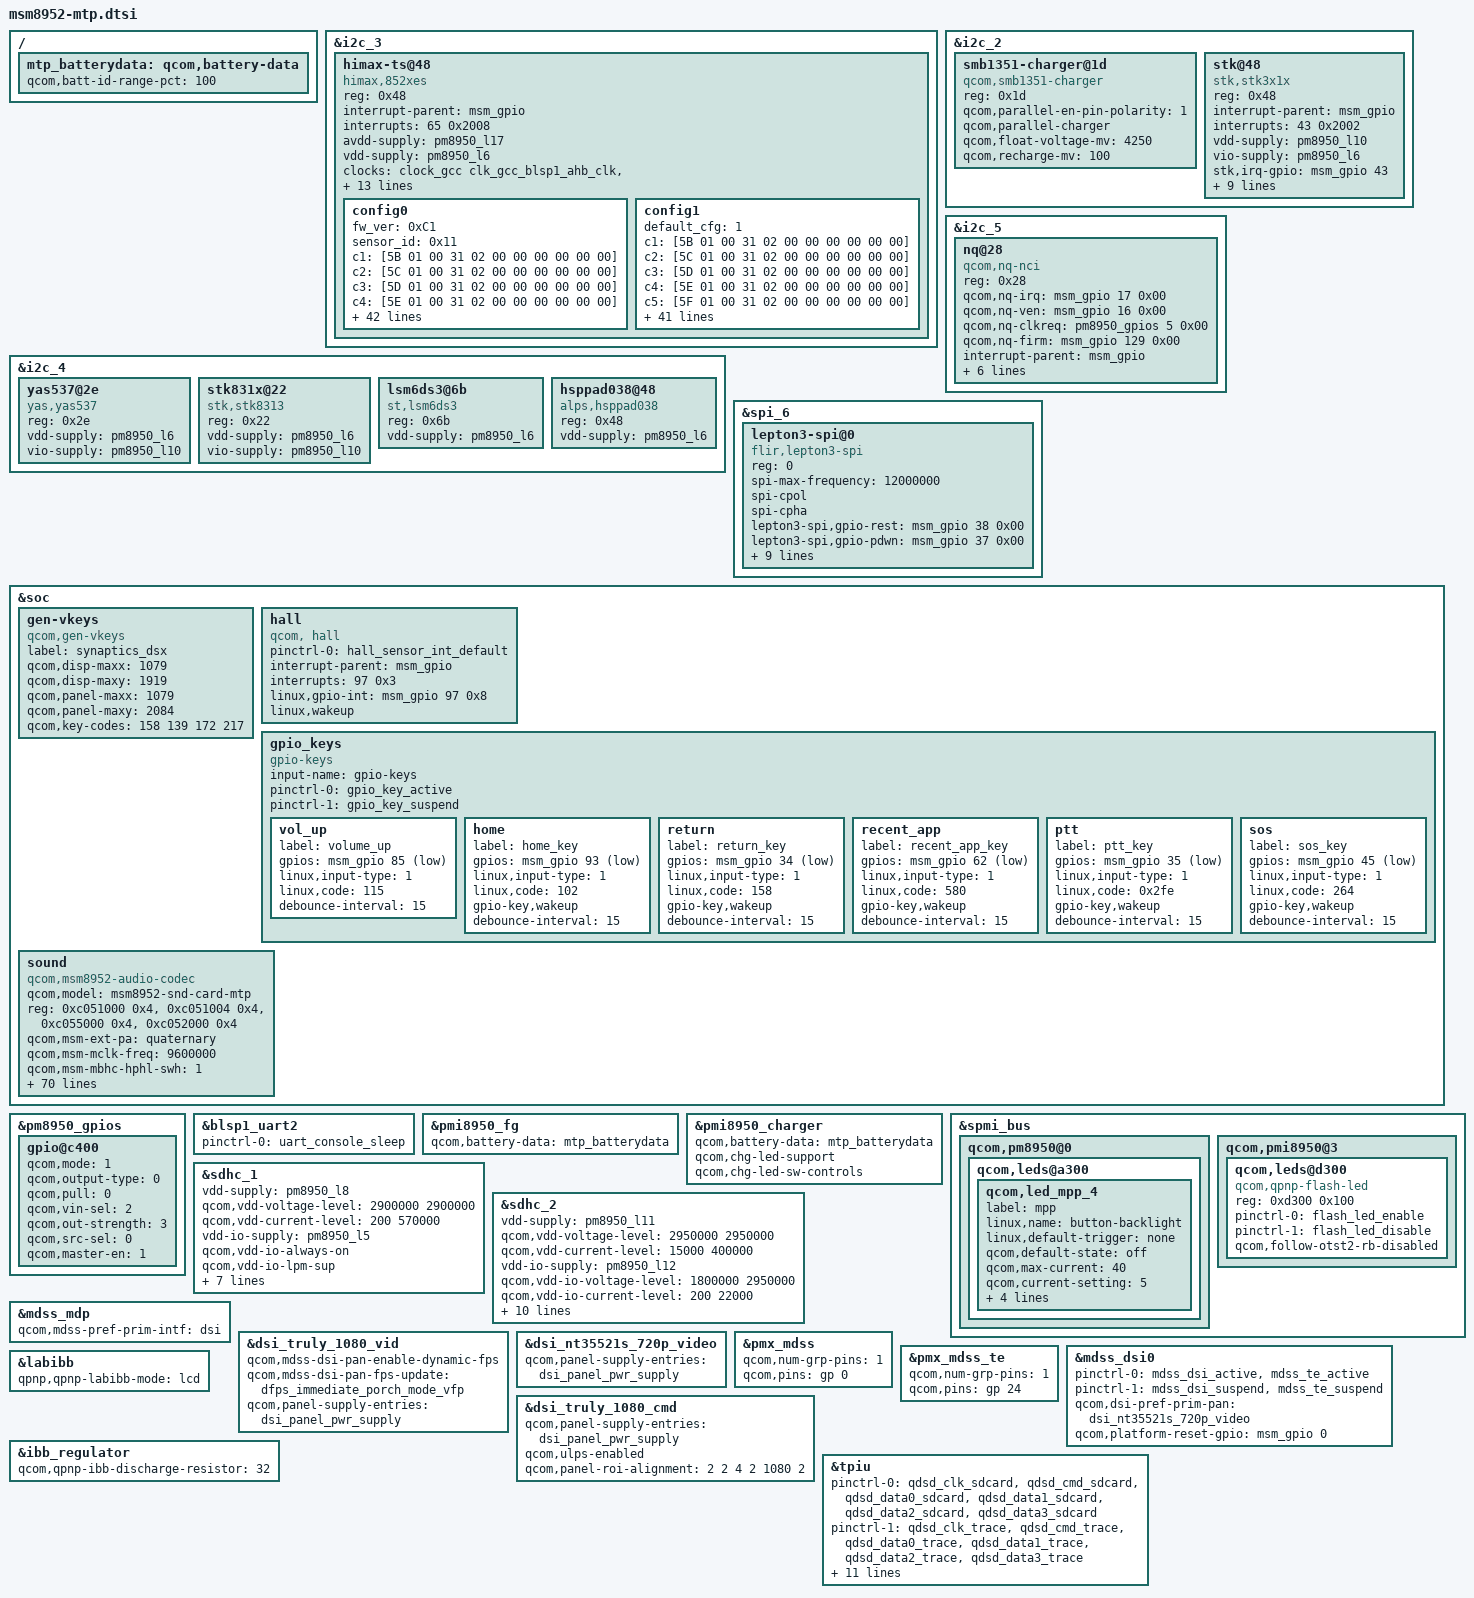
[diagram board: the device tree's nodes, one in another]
/*
 * Copyright (c) 2015, The Linux Foundation. All rights reserved.
 *
 * This program is free software; you can redistribute it and/or modify
 * it under the terms of the GNU General Public License version 2 and
 * only version 2 as published by the Free Software Foundation.
 *
 * This program is distributed in the hope that it will be useful,
 * but WITHOUT ANY WARRANTY; without even the implied warranty of
 * MERCHANTABILITY or FITNESS FOR A PARTICULAR PURPOSE.  See the
 * GNU General Public License for more details.
 */

#include "msm8952.dtsi"
#include "msm8952-pinctrl.dtsi"
#include "msm8952-camera-sensor-mtp.dtsi"

&i2c_3 { /* BLSP1 QUP3 */
	himax-ts@48 {
		compatible = "himax,852xes";
		reg = <0x48>;
		interrupt-parent = <&msm_gpio>;
		interrupts = <65 0x2008>;
		avdd-supply = <&pm8950_l17>;
		vdd-supply = <&pm8950_l6>;
		clock-names = "iface_clk", "core_clk";
		clocks = <&clock_gcc clk_gcc_blsp1_ahb_clk>,
			<&clock_gcc clk_gcc_blsp1_qup3_i2c_apps_clk>;
		/* pins used by touchscreen */
		pinctrl-names = "pmx_ts_active","pmx_ts_suspend","pmx_ts_release";
		pinctrl-0 = <&ts_int_active &ts_reset_active>;
		pinctrl-1 = <&ts_int_suspend &ts_reset_suspend>;
		pinctrl-2 = <&ts_release>;
		himax,irq-gpio = <&msm_gpio 65 0x2008>;
		himax,rst-gpio = <&msm_gpio 64 0x0>;
		himax,i2c-pull-up;
		himax,power-down;
		himax,disable-gpios;
		himax,bypass-packrat-id-check;
		himax,display-coords = <0 720 0 1280>;
		himax,panel-coords = <0 720 0 1280>;
		report_type = <1>;
		config0 {       //Wintek
			fw_ver          = <0xC1>;
			sensor_id       = <0x11>;
			
			c1  = [5B 01 00 31 02 00 00 00 00 00 00];
			c2  = [5C 01 00 31 02 00 00 00 00 00 00];
			c3  = [5D 01 00 31 02 00 00 00 00 00 00];
			c4  = [5E 01 00 31 02 00 00 00 00 00 00];
			c5  = [5F 01 00 31 02 00 00 00 00 00 00];
			c6  = [60 01 00 31 02 00 00 00 00 00 00];
			c7  = [61 01 00 31 02 00 00 00 00 00 00];
			c8  = [62 01 00 31 02 00 00 00 00 00 00];
			c9  = [63 01 00 01 02 00 00 00 00 00 00];
			c10 = [64 01 00 01 02 00 00 00 00 00 00];
			c11 = [65 01 00 01 02 00 00 00 00 00 00];
			c12 = [66 01 00 01 02 00 00 00 00 00 00];
			c13 = [67 01 00 21 00 00 00 00 00 00 00];
			c14 = [68 01 00 01 00 00 00 00 00 00 00];
			c15 = [69 01 00 01 00 00 00 00 00 00 00];
			c16 = [6A 00 00 20 01 00 00 00 00 00 00];
			c17 = [6B 00 00 20 01 00 00 00 00 00 00];
			c18 = [D5 29 00 00 00 00 00 00 00 00 00
			       00 00 00 00 00 00];
			c19 = [E1 03 01 02 02 02
			       03 0F 03 0F 03 0F 03 0F 08];
			c20 = [BC 00 00 00 00];
			c21 = [C5 0A 1F 00 10 16 1A 0B 1F 02 1F];
			c22 = [C6 12 10 18];
			c23 = [BD 00 0B];
			c24 = [B9 01 15];
			c25 = [EC 00 D8 8C];
			c26 = [B0 00];
			c27 = [DD 03];
			c28 = [42 02];
			c29 = [CE 00];
			c30 = [CA 00];
			c31 = [3F 00];
			c32 = [EB 03];
			c33 = [BA 00];
			c34 = [BB 00];
			c35 = [D3 06 01];
			c36 = [37 FF 08 FF 08];
			c37 = [A4 94 62 94 86];
			c38 = [ED 00 04 0A 0A 04 00 00 00];
			c39 = [CB 00 0F 0F FF FF 01 00 0A 00 32
			       00 FF 00];
			c40 = [40 03 5A
			       5F 04 F0 14 04 00
			       1C 0C 0B 0C 08 08 08 0C 0C 0C
			       24 20 40 40 20 00 00 00 00 00
			       00 00
			       94 0A F0 82 86 00
			       48 24 0F 0F 83 3C 00 00
			       11 00 41 42 18 38 00 12 00 00
			       10 01 1C 64 00 00
			       18 3F 3F 02 1F 00 00 00
			       04 06 24 03 03 00 00 00
			       A5 40 0A 00 00 D8 8C 20 00 02
			       03 10 00 00 00 00
			       10 02 80 00 00 00 00 0C
			       10 17 20 32 01 06 0B 00
			       C8 72 2D 00
			       0F 19 A0 13
			       00 00 04 38 07 80
			       02 60 06 3B 53 33 08 00 7A 02 23 53 67 0A
			       03 5F 08 D8 57 64 00 00 B9 03 40 56 75 00
			       00 00 00 00 00 00 00 00];
			c41 = [40 00 01 02 03 04 05 06 07 08 09
			       0A 0B 0C 0D 0E 27 26
			       25 24 23 22 21 20 1F 1E 1D 1C
			       1B 1A 19 FF FF 18 17
			       16 15 14 13 12 11 10 0F FF FF
			       FF FF FF FF FF FF FF
			       FF FF FF
			       00 00 00 00 00 00
			       00 00 00 00 00 00 00 00 00 00
			       00 00 00 8F 00 00 00 00 00 00
			       11 C4 45 C5 48 5C 03 00 00 00
			       00 00 00 00 00 00
			       00 00];
		};
		config1 {       //O-film
			default_cfg     = <1>;
			
			c1  = [5B 01 00 31 02 00 00 00 00 00 00];
			c2  = [5C 01 00 31 02 00 00 00 00 00 00];
			c3  = [5D 01 00 31 02 00 00 00 00 00 00];
			c4  = [5E 01 00 31 02 00 00 00 00 00 00];
			c5  = [5F 01 00 31 02 00 00 00 00 00 00];
			c6  = [60 01 00 31 02 00 00 00 00 00 00];
			c7  = [61 01 00 31 02 00 00 00 00 00 00];
			c8  = [62 01 00 31 02 00 00 00 00 00 00];
			c9  = [63 01 00 01 02 00 00 00 00 00 00];
			c10 = [64 01 00 01 02 00 00 00 00 00 00];
			c11 = [65 01 00 01 02 00 00 00 00 00 00];
			c12 = [66 01 00 01 02 00 00 00 00 00 00];
			c13 = [67 01 00 21 00 00 00 00 00 00 00];
			c14 = [68 01 00 01 00 00 00 00 00 00 00];
			c15 = [69 01 00 01 00 00 00 00 00 00 00];
			c16 = [6A 00 00 20 01 00 00 00 00 00 00];
			c17 = [6B 00 00 20 01 00 00 00 00 00 00];
			c18 = [D5 29 00 00 00 00 00 00 00 00 00
			       00 00 00 00 00 00];
			c19 = [E1 03 01 02 02 02
			       03 0F 03 0F 03 0F 03 0F 08];
			c20 = [BC 00 00 00 00];
			c21 = [C5 0A 1F 00 10 16 1A 0B 1F 02 1F];
			c22 = [C6 12 10 18];
			c23 = [BD 00 0B];
			c24 = [B9 01 15];
			c25 = [EC 00 D8 8C];
			c26 = [B0 00];
			c27 = [DD 03];
			c28 = [42 02];
			c29 = [CE 00];
			c30 = [CA 00];
			c31 = [3F 00];
			c32 = [EB 03];
			c33 = [BA 00];
			c34 = [BB 00];
			c35 = [D3 06 01];
			c36 = [37 FF 08 FF 08];
			c37 = [A4 94 62 94 86];
			c38 = [ED 00 04 0A 0A 04 00 00 00];
			c39 = [CB 00 0F 0F FF FF 01 00 0A 00 32
			       00 FF 00];
			c40 = [40 03 5A
			       5F 04 F0 14 04 00
			       1C 0C 0B 0C 08 08 08 0C 0C 0C
			       24 20 40 40 20 00 00 00 00 00
			       00 00
			       94 0A F0 82 86 00
			       48 24 0F 0F 83 3C 00 00
			       11 00 41 42
			       18 38 00 12 00 00
			       10 01 1C 64 00 00
			       18 3F 3F 02 1F 00 00 00
			       04 06 24 03 03 00 00 00
			       A5 40 0A 00 00 D8 8C 20 00 02
			       03 10 00 00 00 00
			       10 02 80 00 00 00 00 0C
			       10 17 20 32 01 06 0B 00
			       C8 72 2D 00
			       0F 19 A0 13
			       00 00 04 38 07 80
			       02 60 06 3B 53 33 08 00 7A 02 23 53 67 0A
			       03 5F 08 D8 57 64 00 00 B9 03 40 56 75 00
			       00 00 00 00 00 00 00 00];
			c41 = [40 00 01 02 03 04 05 06 07 08 09
			       0A 0B 0C 0D 0E 27 26
			       25 24 23 22 21 20 1F 1E 1D 1C
			       1B 1A 19 FF FF 18 17
			       16 15 14 13 12 11 10 0F FF FF
			       FF FF FF FF FF FF FF
			       FF FF FF
			       00 00 00 00 00 00
			       00 00 00 00 00 00 00 00 00 00
			       00 00 00 8F 00 00 00 00 00 00
			       11 C4 45 C5 48 5C 03 00 00 00
			       00 00 00 00 00 00
			       00 00];
		};
	};
};

&i2c_2 {
	/* Parallel-charger configuration */
	smb1351-charger@1d {
		compatible = "qcom,smb1351-charger";
		reg = <0x1d>;
		qcom,parallel-en-pin-polarity = <1>;
		qcom,parallel-charger;
		qcom,float-voltage-mv = <4250>;
		qcom,recharge-mv = <100>;
	};
	stk@48 { /* stk3311 p sensor */
		compatible = "stk,stk3x1x";
		reg = <0x48>;
		interrupt-parent = <&msm_gpio>;
		interrupts = <43 0x2002>;
		vdd-supply = <&pm8950_l10>;
		vio-supply = <&pm8950_l6>;
		stk,irq-gpio = <&msm_gpio 43 0x2002>;
		stk,state-reg = <0x0>;
		stk,psctrl-reg = <0x31>;
		stk,alsctrl-reg = <0x38>;
		stk,ledctrl-reg = <0xFF>;
		stk,wait-reg = <0x07>;
		stk,ps-thd-h = <1700>;
		stk,ps-thd-l = <1500>;
		stk,transmittance = <500>;
		stk,use-fir;
	};
};

&i2c_4 {/* BLSP1 QUP4*/
	yas537@2e { /* Magnetic field sensor */
                compatible = "yas,yas537";
                reg = <0x2e>;
                vdd-supply = <&pm8950_l6>;
                vio-supply = <&pm8950_l10>;
        };

        stk831x@22 { /*Sensortek Stk8313 accelerometer sensor*/
                compatible = "stk,stk8313";
                reg = <0x22>;
                vdd-supply = <&pm8950_l6>;
                vio-supply = <&pm8950_l10>;
        };

	lsm6ds3@6b { /*ST LSM6DS3 accelerometer + gyroscope sensor*/
		compatible = "st,lsm6ds3";
		reg = <0x6b>;
		vdd-supply = <&pm8950_l6>;
	};

	hsppad038@48 {
		compatible = "alps,hsppad038";
                reg = <0x48>;
                vdd-supply = <&pm8950_l6>;
	};
};

&i2c_5 { /* BLSP2 QUP1 */
	nq@28 {
		compatible = "qcom,nq-nci";
		reg = <0x28>;
		qcom,nq-irq = <&msm_gpio 17 0x00>;
		qcom,nq-ven = <&msm_gpio 16 0x00>;
		qcom,nq-clkreq = <&pm8950_gpios 5 0x00>;
		qcom,nq-firm = <&msm_gpio 129 0x00>;
		interrupt-parent = <&msm_gpio>;
		qcom,clk-src = "BBCLK2";
		interrupts = <17 0>;
		interrupt-names = "nfc_irq";
		pinctrl-names = "nfc_active", "nfc_suspend";
		pinctrl-0 = <&nfc_int_active &nfc_disable_active>;
		pinctrl-1 = <&nfc_int_suspend &nfc_disable_suspend>;
		clocks = <&clock_gcc clk_bb_clk2_pin>;
		clock-names = "ref_clk";
	};
};

&spi_6 { 
	lepton3-spi@0 { //Slave driver and CS ID
		compatible = "flir,lepton3-spi"; //Manufacture, and Model
		reg = <0>; //Same as CS ID
		spi-max-frequency = <12000000>;
		spi-cpol; //CPOL bit set for SPI polarity
		spi-cpha; //CPHA bit set for SPI Phase
		lepton3-spi,gpio-rest = <&msm_gpio 38 0x00>;
		lepton3-spi,gpio-pdwn = <&msm_gpio 37 0x00>;
		lepton3-spi,gpio-vsync = <&msm_gpio 1 0x00>;
		lepton3-spi,gpio-vddc-en = <&msm_gpio 60 0x00>;
		lepton3-spi,gpio-vddcio-en = <&msm_gpio 61 0x00>;
		lepton3-spi,gpio-vdd-en = <&msm_gpio 133 0x00>;
		vddp4-supply = <&pm8950_l14>;
		i2cpull-supply = <&pm8950_l5>;
		levelshift-supply = <&pm8950_l6>;
		pinctrl-names = "lepton_active", "lepton_suspend";
		pinctrl-0 = <&lepton_active &lepton_suspend>;
		pinctrl-1 = <&lepton_active &lepton_suspend>;
	};
};

&soc {
	gen-vkeys {
		compatible = "qcom,gen-vkeys";
		label = "synaptics_dsx";
		qcom,disp-maxx = <1079>;
		qcom,disp-maxy = <1919>;
		qcom,panel-maxx = <1079>;
		qcom,panel-maxy = <2084>;
		qcom,key-codes = <158 139 172 217>;
	};
	//start:CEI_ANDROID
        hall{
               compatible = "qcom, hall";
               pinctrl-names = "default";
               pinctrl-0 = <&hall_sensor_int_default>;
               interrupt-parent = <&msm_gpio>;
               interrupts = <97 0x3>;
               linux,gpio-int = <&msm_gpio 97 0x8>;
               linux,wakeup;
        };
	//end:CEI_ANDROID
	gpio_keys {
		compatible = "gpio-keys";
		input-name = "gpio-keys";
		pinctrl-names = "tlmm_gpio_key_active","tlmm_gpio_key_suspend";
		pinctrl-0 = <&gpio_key_active>;
		pinctrl-1 = <&gpio_key_suspend>;
/*
		camera_focus {
			label = "camera_focus";
			gpios = <&msm_gpio 87 0x1>;
			linux,input-type = <1>;
			linux,code = <0x210>;
			debounce-interval = <15>;
		};

		camera_snapshot {
			label = "camera_snapshot";
			gpios = <&msm_gpio 86 0x1>;
			linux,input-type = <1>;
			linux,code = <0x2fe>;
			debounce-interval = <15>;
		};
*/
		vol_up {
			label = "volume_up";
			gpios = <&msm_gpio 85 0x1>;
			linux,input-type = <1>;
			linux,code = <115>;
			debounce-interval = <15>;
		};
		home {
			label = "home_key";
			gpios = <&msm_gpio 93 0x1>;
			linux,input-type = <1>;
			linux,code = <102>;
			gpio-key,wakeup;
			debounce-interval = <15>;
		};
		return {
			label = "return_key";
			gpios = <&msm_gpio 34 0x1>;
			linux,input-type = <1>;
			linux,code = <158>;
			gpio-key,wakeup;
			debounce-interval = <15>;
		};
		recent_app {
			label = "recent_app_key";
			gpios = <&msm_gpio 62 0x1>;
			linux,input-type = <1>;
			linux,code = <580>;
			gpio-key,wakeup;
			debounce-interval = <15>;
		};
		ptt {
			label = "ptt_key";
			gpios = <&msm_gpio 35 0x1>;
			linux,input-type = <1>;
			linux,code = <0x2fe>;
			gpio-key,wakeup;
			debounce-interval = <15>;
		};
		sos {
			label = "sos_key";
			gpios = <&msm_gpio 45 0x1>;
			linux,input-type = <1>;
			linux,code = <264>;
			gpio-key,wakeup;
			debounce-interval = <15>;
		};
	};

	 sound {
		compatible = "qcom,msm8952-audio-codec";
		qcom,model = "msm8952-snd-card-mtp";
		reg = <0xc051000 0x4>,
		      <0xc051004 0x4>,
		      <0xc055000 0x4>,
		      <0xc052000 0x4>;
		reg-names = "csr_gp_io_mux_mic_ctl",
			    "csr_gp_io_mux_spkr_ctl",
			    "csr_gp_io_lpaif_pri_pcm_pri_mode_muxsel",
			    "csr_gp_io_mux_quin_ctl";

		qcom,msm-ext-pa = "quaternary";
		qcom,msm-mclk-freq = <9600000>;
		qcom,msm-mbhc-hphl-swh = <1>;
		qcom,msm-mbhc-gnd-swh = <1>;
		qcom,msm-hs-micbias-type = "internal";
		qcom,msm-micbias1-ext-cap;
		qcom,audio-routing =
			"RX_BIAS", "MCLK",
			"SPK_RX_BIAS", "MCLK",
			"INT_LDO_H", "MCLK",
			"MIC BIAS External", "Digital Mic1",
			"MIC BIAS Internal2", "Headset Mic",
			"MIC BIAS External", "Digital Mic2",
			"DMIC1", "MIC BIAS External",
			"AMIC2", "MIC BIAS Internal2",
			"DMIC2", "MIC BIAS External";
			//"WSA_SPK OUT", "VDD_WSA_SWITCH",
			//"SpkrMono WSA_IN", "WSA_SPK OUT";
		qcom,msm-gpios =
			"pri_i2s",
			"quat_i2s",
			"us_eu_gpio";
		qcom,pinctrl-names =
			"all_off",
			"pri_i2s_act",
			"quat_i2s_act",
			"quat_i2s_sus",
			"cdc_lines_dmic_act",
			"cdc_lines_dmic_sus",
			"us_eu_gpio_act",
			"pri_i2s_us_eu_gpio_act";
		pinctrl-names =
			"all_off",
			"pri_i2s_act",
			"quat_i2s_act",
			"quat_i2s_sus",
			"cdc_lines_dmic_act",
			"cdc_lines_dmic_sus",
			"us_eu_gpio_act",
			"pri_i2s_us_eu_gpio_act";
		pinctrl-0 = <&cdc_pdm_lines_sus &cdc_pdm_lines_2_sus &cross_conn_det_sus &quat_i2s_act &cdc_lines_dmic_sus>;
		pinctrl-1 = <&cdc_pdm_lines_act &cdc_pdm_lines_2_act &cross_conn_det_sus &quat_i2s_act &cdc_lines_dmic_act>;
		pinctrl-2 = <&cdc_pdm_lines_sus &cdc_pdm_lines_2_sus &cross_conn_det_act &quat_i2s_act &cdc_lines_dmic_act>;
		pinctrl-3 = <&cdc_pdm_lines_act &cdc_pdm_lines_2_act &cross_conn_det_act &quat_i2s_act &cdc_lines_dmic_sus>;
		pinctrl-4 = <&cdc_pdm_lines_act &cdc_pdm_lines_2_act &cross_conn_det_act &quat_i2s_act &cdc_lines_dmic_act>;
		pinctrl-5 = <&cdc_pdm_lines_sus &cdc_pdm_lines_2_sus &cross_conn_det_act &quat_i2s_act &cdc_lines_dmic_sus>;
		qcom,cdc-us-euro-gpios = <&msm_gpio 63 0>;
		asoc-platform = <&pcm0>, <&pcm1>, <&pcm2>, <&voip>, <&voice>,
				<&loopback>, <&compress>, <&hostless>,
				<&afe>, <&lsm>, <&routing>, <&lpa>,
				<&voice_svc>;
		asoc-platform-names = "msm-pcm-dsp.0", "msm-pcm-dsp.1", "msm-pcm-dsp.2",
				"msm-voip-dsp", "msm-pcm-voice", "msm-pcm-loopback",
				"msm-compress-dsp", "msm-pcm-hostless", "msm-pcm-afe",
				"msm-lsm-client", "msm-pcm-routing", "msm-pcm-lpa",
				"msm-voice-svc";
		asoc-cpu = <&dai_pri_auxpcm>, <&dai_hdmi>,
				<&dai_mi2s0>, <&dai_mi2s1>, <&dai_mi2s2>, <&dai_mi2s3>,
				<&dai_mi2s5>, <&dai_mi2s6>,
				<&sb_0_rx>, <&sb_0_tx>, <&sb_1_rx>, <&sb_1_tx>,
				<&sb_3_rx>, <&sb_3_tx>, <&sb_4_rx>, <&sb_4_tx>,
				<&bt_sco_rx>, <&bt_sco_tx>, <&int_fm_rx>, <&int_fm_tx>,
				<&afe_pcm_rx>, <&afe_pcm_tx>, <&afe_proxy_rx>, <&afe_proxy_tx>,
				<&incall_record_rx>, <&incall_record_tx>, <&incall_music_rx>,
				<&incall_music_2_rx>;
		asoc-cpu-names = "msm-dai-q6-auxpcm.1", "msm-dai-q6-hdmi.8",
				"msm-dai-q6-mi2s.0", "msm-dai-q6-mi2s.1",
				"msm-dai-q6-mi2s.2", "msm-dai-q6-mi2s.3",
				"msm-dai-q6-mi2s.5", "msm-dai-q6-mi2s.6",
				"msm-dai-q6-dev.16384", "msm-dai-q6-dev.16385",
				"msm-dai-q6-dev.16386", "msm-dai-q6-dev.16387",
				"msm-dai-q6-dev.16390", "msm-dai-q6-dev.16391",
				"msm-dai-q6-dev.16392", "msm-dai-q6-dev.16393",
				"msm-dai-q6-dev.12288", "msm-dai-q6-dev.12289",
				"msm-dai-q6-dev.12292", "msm-dai-q6-dev.12293",
				"msm-dai-q6-dev.224", "msm-dai-q6-dev.225",
				"msm-dai-q6-dev.241", "msm-dai-q6-dev.240",
				"msm-dai-q6-dev.32771", "msm-dai-q6-dev.32772",
				"msm-dai-q6-dev.32773", "msm-dai-q6-dev.32770";
		asoc-codec = <&stub_codec>, <&pm8950_cajon_dig>;
		asoc-codec-names = "msm-stub-codec.1", "cajon_codec";
		//asoc-wsa-codec-names = "wsa881x-i2c-codec.8-000f";
		//asoc-wsa-codec-prefixes = "SpkrMono";

		//msm-vdd-wsa-switch-supply = <&pm8950_l13>;
		//qcom,msm-vdd-wsa-switch-voltage = <3075000>;
		//qcom,msm-vdd-wsa-switch-current = <5000>;
	};

/*
	i2c@7af8000 {
		wsa881x-i2c-codec@e {
			compatible = "qcom,wsa881x-i2c-codec";
			reg = <0x0e>;
			qcom,msm-gpios = "wsa_clk",
					"wsa_reset",
					"wsa_vi";
			qcom,pinctrl-names = "all_off",
					"wsa_clk",
					"wsa_active",
					"wsa_clk_active",
					"wsa_vi",
					"wsa_clk_vi",
					"wsa_active_vi",
					"wsa_all";
			pinctrl-names = "all_off",
					"wsa_clk",
					"wsa_active",
					"wsa_clk_active",
					"wsa_vi",
					"wsa_clk_vi",
					"wsa_active_vi",
					"wsa_all";
			pinctrl-0 = <&wsa_clk_off &wsa_suspend &wsa_vi_sus>;
			pinctrl-1 = <&wsa_clk_on &wsa_suspend &wsa_vi_sus>;
			pinctrl-2 = <&wsa_clk_off &wsa_active &wsa_vi_sus>;
			pinctrl-3 = <&wsa_clk_on &wsa_active &wsa_vi_sus>;
			pinctrl-4 = <&wsa_clk_off &wsa_suspend &wsa_vi_act>;
			pinctrl-5 = <&wsa_clk_on &wsa_suspend &wsa_vi_act>;
			pinctrl-6 = <&wsa_clk_off &wsa_active &wsa_vi_act>;
			pinctrl-7 = <&wsa_clk_on &wsa_active &wsa_vi_act>;
		};
		wsa881x-i2c-codec@44 {
			compatible = "qcom,wsa881x-i2c-codec";
			reg = <0x44>;
		};
		wsa881x-i2c-codec@f {
			compatible = "qcom,wsa881x-i2c-codec";
			reg = <0x0f>;
			qcom,msm-gpios = "wsa_clk",
					"wsa_reset",
					"wsa_vi";
			qcom,pinctrl-names = "all_off",
					"wsa_clk",
					"wsa_active",
					"wsa_clk_active",
					"wsa_vi",
					"wsa_clk_vi",
					"wsa_active_vi",
					"wsa_all";
			pinctrl-names = "all_off",
					"wsa_clk",
					"wsa_active",
					"wsa_clk_active",
					"wsa_vi",
					"wsa_clk_vi",
					"wsa_active_vi",
					"wsa_all";
			pinctrl-0 = <&wsa_clk_off &wsa_suspend &wsa_vi_sus>;
			pinctrl-1 = <&wsa_clk_on &wsa_suspend &wsa_vi_sus>;
			pinctrl-2 = <&wsa_clk_off &wsa_active &wsa_vi_sus>;
			pinctrl-3 = <&wsa_clk_on &wsa_active &wsa_vi_sus>;
			pinctrl-4 = <&wsa_clk_off &wsa_suspend &wsa_vi_act>;
			pinctrl-5 = <&wsa_clk_on &wsa_suspend &wsa_vi_act>;
			pinctrl-6 = <&wsa_clk_off &wsa_active &wsa_vi_act>;
			pinctrl-7 = <&wsa_clk_on &wsa_active &wsa_vi_act>;
		};
		wsa881x-i2c-codec@45 {
			compatible = "qcom,wsa881x-i2c-codec";
			reg = <0x45>;
		};
	};
*/
};

&pm8950_gpios {
	gpio@c400 {
		qcom,mode = <1>;
		qcom,output-type = <0>;
		qcom,pull = <0>;
		qcom,vin-sel = <2>;
		qcom,out-strength = <3>;
		qcom,src-sel = <0>;
		qcom,master-en = <1>;
		status = "okay";
	};
};

&blsp1_uart2 {
	status = "ok";
	pinctrl-names = "default";
	pinctrl-0 = <&uart_console_sleep>;
};

/{
	mtp_batterydata: qcom,battery-data {
		qcom,batt-id-range-pct = <100>;
		/* #include "batterydata-itech-3000mah-4200mv.dtsi" */
		/*#include "batterydata-itech-3000mah.dtsi"*/
		#include "BT52_3700mAh_PMI8950GUI20015.dtsi"
	};
};

&pmi8950_fg {
	qcom,battery-data = <&mtp_batterydata>;
};

&pmi8950_charger {
	qcom,battery-data = <&mtp_batterydata>;
	qcom,chg-led-support;
	qcom,chg-led-sw-controls;
};

&spmi_bus {
	qcom,pm8950@0 {
		qcom,leds@a300 {
			status = "okay";
			qcom,led_mpp_4 {
				label = "mpp";
				linux,name = "button-backlight";
				linux,default-trigger = "none";
				qcom,default-state = "off";
				qcom,max-current = <40>;
				qcom,current-setting = <5>;
				qcom,id = <6>;
				qcom,mode = "manual";
				qcom,source-sel = <1>;
				qcom,mode-ctrl = <0x60>;
			};
		};
	};

	qcom,pmi8950@3 {
		qcom,leds@d300 {
			compatible = "qcom,qpnp-flash-led";
			status = "okay";
			reg = <0xd300 0x100>;
			pinctrl-names = "flash_led_enable","flash_led_disable";
			pinctrl-0 = <&flash_led_enable>;
			pinctrl-1 = <&flash_led_disable>;
			qcom,follow-otst2-rb-disabled;
		};
	};
};

&sdhc_1 {
	vdd-supply = <&pm8950_l8>;
	qcom,vdd-voltage-level = <2900000 2900000>;
	qcom,vdd-current-level = <200 570000>;

	vdd-io-supply = <&pm8950_l5>;
	qcom,vdd-io-always-on;
	qcom,vdd-io-lpm-sup;
	qcom,vdd-io-voltage-level = <1800000 1800000>;
	qcom,vdd-io-current-level = <200 325000>;

	pinctrl-names = "active", "sleep";
	pinctrl-0 = <&sdc1_clk_on &sdc1_cmd_on &sdc1_data_on &sdc1_rclk_on>;
	pinctrl-1 = <&sdc1_clk_off &sdc1_cmd_off &sdc1_data_off &sdc1_rclk_off>;

	qcom,nonremovable;

	status = "ok";
};

&sdhc_2 {
	vdd-supply = <&pm8950_l11>;
	qcom,vdd-voltage-level = <2950000 2950000>;
	qcom,vdd-current-level = <15000 400000>;

	vdd-io-supply = <&pm8950_l12>;
	qcom,vdd-io-voltage-level = <1800000 2950000>;
	qcom,vdd-io-current-level = <200 22000>;

	pinctrl-names = "active", "sleep";
	pinctrl-0 = <&sdc2_clk_on &sdc2_cmd_on &sdc2_data_on &sdc2_cd_on>;
	pinctrl-1 = <&sdc2_clk_off &sdc2_cmd_off &sdc2_data_off &sdc2_cd_off>;

	#address-cells = <0>;
	interrupt-parent = <&sdhc_2>;
	interrupts = <0 1 2>;
	#interrupt-cells = <1>;
	interrupt-map-mask = <0xffffffff>;
	interrupt-map = <0 &intc 0 125 0
			1 &intc 0 221 0
			2 &msm_gpio 67 0>;
	interrupt-names = "hc_irq", "pwr_irq", "status_irq";
	cd-gpios = <&msm_gpio 67 0x1>;

	status = "ok";
};

&mdss_mdp {
	qcom,mdss-pref-prim-intf = "dsi";
};

&dsi_truly_1080_vid {
	qcom,mdss-dsi-pan-enable-dynamic-fps;
	qcom,mdss-dsi-pan-fps-update = "dfps_immediate_porch_mode_vfp";
	qcom,panel-supply-entries = <&dsi_panel_pwr_supply>;
};

/* CEI sam add for LCM porting */
&dsi_nt35521s_720p_video {
	qcom,panel-supply-entries = <&dsi_panel_pwr_supply>;
};


&pmx_mdss {
	qcom,num-grp-pins = <1>;
	qcom,pins = <&gp 0>;
};

&pmx_mdss_te {
	qcom,num-grp-pins = <1>;
	qcom,pins = <&gp 24>;
};

&mdss_dsi0 {
	pinctrl-names = "mdss_default", "mdss_sleep";
	pinctrl-0 = <&mdss_dsi_active &mdss_te_active>;
	pinctrl-1 = <&mdss_dsi_suspend &mdss_te_suspend>;
	/* CEI sam change for LCM porting */
	qcom,dsi-pref-prim-pan = <&dsi_nt35521s_720p_video>;

	qcom,platform-reset-gpio = <&msm_gpio 0 0>;
};

&dsi_truly_1080_cmd {
	qcom,panel-supply-entries = <&dsi_panel_pwr_supply>;
	qcom,ulps-enabled;
	qcom,panel-roi-alignment = <2 2 4 2 1080 2>;
};

&labibb {
	status = "ok";
	qpnp,qpnp-labibb-mode = "lcd";
};

&ibb_regulator {
	qcom,qpnp-ibb-discharge-resistor = <32>;
};

/* CoreSight */
&tpiu {
	pinctrl-names = "sdcard", "trace", "swduart",
			"swdtrc", "jtag", "spmi";
	/* NIDnT */
	pinctrl-0 = <&qdsd_clk_sdcard &qdsd_cmd_sdcard
		     &qdsd_data0_sdcard &qdsd_data1_sdcard
		     &qdsd_data2_sdcard &qdsd_data3_sdcard>;
	pinctrl-1 = <&qdsd_clk_trace &qdsd_cmd_trace
		     &qdsd_data0_trace &qdsd_data1_trace
		     &qdsd_data2_trace &qdsd_data3_trace>;
	pinctrl-2 = <&qdsd_cmd_swduart &qdsd_data0_swduart
		     &qdsd_data1_swduart &qdsd_data2_swduart
		     &qdsd_data3_swduart>;
	pinctrl-3 = <&qdsd_clk_swdtrc &qdsd_cmd_swdtrc
		     &qdsd_data0_swdtrc &qdsd_data1_swdtrc
		     &qdsd_data2_swdtrc &qdsd_data3_swdtrc>;
	pinctrl-4 = <&qdsd_cmd_jtag &qdsd_data0_jtag
		     &qdsd_data1_jtag &qdsd_data2_jtag
		     &qdsd_data3_jtag>;
	pinctrl-5 = <&qdsd_clk_spmi &qdsd_cmd_spmi
		     &qdsd_data0_spmi &qdsd_data3_spmi>;
};
